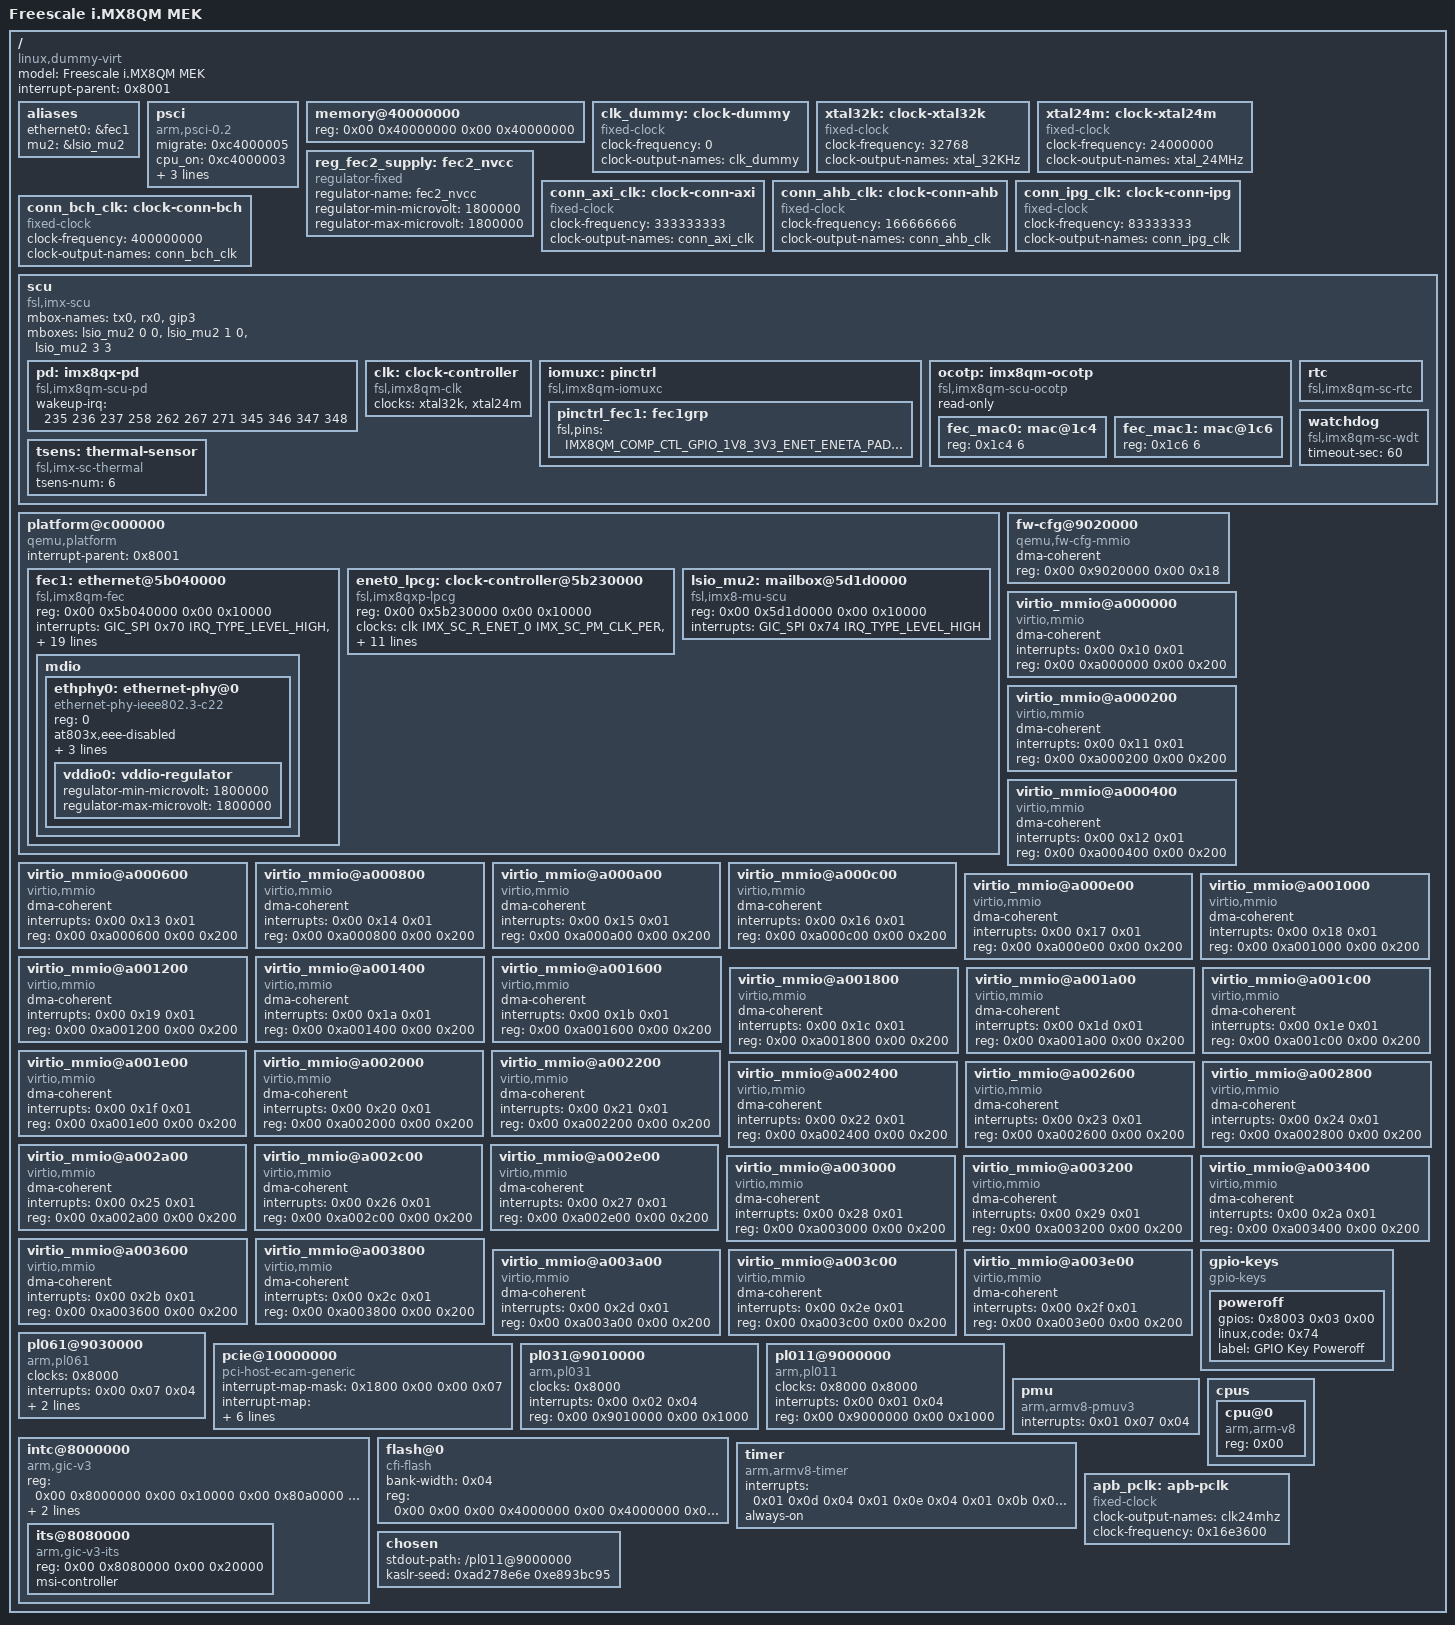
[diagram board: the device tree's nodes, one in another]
// SPDX-FileCopyrightText: 2022-2024 TII (SSRC) and the Ghaf contributors
//
// SPDX-License-Identifier: Apache-2.0

/dts-v1/;

#include <dt-bindings/clock/imx8-clock.h>
#include <dt-bindings/firmware/imx/rsrc.h>
#include <dt-bindings/gpio/gpio.h>
#include <dt-bindings/input/input.h>
#include <dt-bindings/usb/pd.h>
#include <dt-bindings/interrupt-controller/arm-gic.h>
#include <dt-bindings/pinctrl/pads-imx8qm.h>
#include <dt-bindings/soc/imx8_hsio.h>
#include <dt-bindings/thermal/thermal.h>

/ {
	model = "Freescale i.MX8QM MEK";
	interrupt-parent = <0x8001>;
	#size-cells = <0x02>;
	#address-cells = <0x02>;
	compatible = "linux,dummy-virt";

	aliases {
		ethernet0 = &fec1;
		mu2 = &lsio_mu2;
	};

	psci {
		migrate = <0xc4000005>;
		cpu_on = <0xc4000003>;
		cpu_off = <0x84000002>;
		cpu_suspend = <0xc4000001>;
		method = "hvc";
		compatible = "arm,psci-0.2\0arm,psci";
	};

	memory@40000000 {
		reg = <0x00 0x40000000 0x00 0x40000000>;
		device_type = "memory";
	};

	clk_dummy: clock-dummy {
		compatible = "fixed-clock";
		#clock-cells = <0>;
		clock-frequency = <0>;
		clock-output-names = "clk_dummy";
	};

	xtal32k: clock-xtal32k {
		compatible = "fixed-clock";
		#clock-cells = <0>;
		clock-frequency = <32768>;
		clock-output-names = "xtal_32KHz";
	};

	xtal24m: clock-xtal24m {
		compatible = "fixed-clock";
		#clock-cells = <0>;
		clock-frequency = <24000000>;
		clock-output-names = "xtal_24MHz";
	};

	reg_fec2_supply: fec2_nvcc {
		compatible = "regulator-fixed";
		regulator-name = "fec2_nvcc";
		regulator-min-microvolt = <1800000>;
		regulator-max-microvolt = <1800000>;
//		gpio = <&max7322 0 GPIO_ACTIVE_HIGH>;
		status = "okay";
	};

	conn_axi_clk: clock-conn-axi {
		compatible = "fixed-clock";
		#clock-cells = <0>;
		clock-frequency = <333333333>;
		clock-output-names = "conn_axi_clk";
	};

	conn_ahb_clk: clock-conn-ahb {
		compatible = "fixed-clock";
		#clock-cells = <0>;
		clock-frequency = <166666666>;
		clock-output-names = "conn_ahb_clk";
	};

	conn_ipg_clk: clock-conn-ipg {
		compatible = "fixed-clock";
		#clock-cells = <0>;
		clock-frequency = <83333333>;
		clock-output-names = "conn_ipg_clk";
	};

	conn_bch_clk: clock-conn-bch {
		compatible = "fixed-clock";
		#clock-cells = <0>;
		clock-frequency = <400000000>;
		clock-output-names = "conn_bch_clk";
	};

	scu {
		compatible = "fsl,imx-scu";
		mbox-names = "tx0", "rx0", "gip3";
		mboxes = <&lsio_mu2 0 0
			&lsio_mu2 1 0
			&lsio_mu2 3 3>;

		pd: imx8qx-pd {
			compatible = "fsl,imx8qm-scu-pd", "fsl,scu-pd";
			#power-domain-cells = <1>;
			status = "okay";
			wakeup-irq = <235 236 237 258 262 267 271
					345 346 347 348>;
		};

		clk: clock-controller {
			compatible = "fsl,imx8qm-clk", "fsl,scu-clk";
			#clock-cells = <2>;
			clocks = <&xtal32k &xtal24m>;
			clock-names = "xtal_32KHz", "xtal_24Mhz";
		};

		iomuxc: pinctrl {
			compatible = "fsl,imx8qm-iomuxc";
		};

		ocotp: imx8qm-ocotp {
			compatible = "fsl,imx8qm-scu-ocotp";
			#address-cells = <1>;
			#size-cells = <1>;
			read-only;

			fec_mac0: mac@1c4 {
				reg = <0x1c4 6>;
			};

			fec_mac1: mac@1c6 {
				reg = <0x1c6 6>;
			};
		};

		rtc: rtc {
			compatible = "fsl,imx8qm-sc-rtc";
		};

		watchdog {
			compatible = "fsl,imx8qm-sc-wdt", "fsl,imx-sc-wdt";
			timeout-sec = <60>;
		};

		tsens: thermal-sensor {
			compatible = "fsl,imx-sc-thermal";
			tsens-num = <6>;
			#thermal-sensor-cells = <1>;
		};
/*
		secvio: secvio {
			compatible = "fsl,imx-sc-secvio";
			nvmem = <&ocotp>;
		};
*/
	};

	platform@c000000 {
		compatible = "qemu,platform\0simple-bus";
		interrupt-parent = <0x8001>;
		#address-cells = <0x01>;
		#size-cells = <0x01>;

		// ranges = <0xc000000 0x00 0xc000000 0x2000000>;
		ranges = <0x00 0x5b230000 0x00 0xc000000 0x00 0x10000>,
				 <0x00 0x5b040000 0x00 0xc010000 0x00 0x10000>,
				 <0x00 0x5d1d0000 0x00 0xc020000 0x00 0x10000>;
				 

	fec1: ethernet@5b040000 {
		reg = <0x00 0x5b040000 0x00 0x10000>;

		interrupts = <GIC_SPI 258 IRQ_TYPE_LEVEL_HIGH>,
			     <GIC_SPI 256 IRQ_TYPE_LEVEL_HIGH>,
			     <GIC_SPI 257 IRQ_TYPE_LEVEL_HIGH>,
			     <GIC_SPI 259 IRQ_TYPE_LEVEL_HIGH>;

		clocks = <&enet0_lpcg 4>,
			 <&enet0_lpcg 2>,
			 <&enet0_lpcg 3>,
			 <&enet0_lpcg 0>,
			 <&enet0_lpcg 1>;
		clock-names = "ipg", "ahb", "enet_clk_ref", "ptp", "enet_2x_txclk";
		assigned-clocks = <&clk IMX_SC_R_ENET_0 IMX_SC_PM_CLK_PER>,
				  <&clk IMX_SC_R_ENET_0 IMX_SC_C_CLKDIV>;
		assigned-clock-rates = <250000000>, <125000000>;
		fsl,num-tx-queues=<1>;
		fsl,num-rx-queues=<1>;
		power-domains = <&pd IMX_SC_R_ENET_0>;
		status = "disabled";
	};

	enet0_lpcg: clock-controller@5b230000 {
		compatible = "fsl,imx8qxp-lpcg";
		reg = <0x00 0x5b230000 0x00 0x10000>;
		#clock-cells = <1>;
		clocks = <&clk IMX_SC_R_ENET_0 IMX_SC_PM_CLK_PER>,
			 <&clk IMX_SC_R_ENET_0 IMX_SC_PM_CLK_PER>,
			 <&conn_axi_clk>,
			 <&clk IMX_SC_R_ENET_0 IMX_SC_C_TXCLK>,
			 <&conn_ipg_clk>,
			 <&conn_ipg_clk>;
		bit-offset = <0 4 8 12 16 20>;
		clock-output-names = "enet0_lpcg_timer_clk",
					"enet0_lpcg_txc_sampling_clk",
					"enet0_lpcg_ahb_clk",
					"enet0_lpcg_rgmii_txc_clk",
					"enet0_lpcg_ipg_clk",
					"enet0_lpcg_ipg_s_clk";
		power-domains = <&pd IMX_SC_R_ENET_0>;
		status = "disabled";
	};

		lsio_mu2: mailbox@5d1d0000 {
			compatible = "fsl,imx8-mu-scu", "fsl,imx8qm-mu", "fsl,imx6sx-mu";
			reg = <0x00 0x5d1d0000 0x00 0x10000>;
			interrupts = <GIC_SPI 178 IRQ_TYPE_LEVEL_HIGH>;
			#mbox-cells = <0x02>;
			status = "disabled";
		};
	};

	fw-cfg@9020000 {
		dma-coherent;
		reg = <0x00 0x9020000 0x00 0x18>;
		compatible = "qemu,fw-cfg-mmio";
	};

	virtio_mmio@a000000 {
		dma-coherent;
		interrupts = <0x00 0x10 0x01>;
		reg = <0x00 0xa000000 0x00 0x200>;
		compatible = "virtio,mmio";
	};

	virtio_mmio@a000200 {
		dma-coherent;
		interrupts = <0x00 0x11 0x01>;
		reg = <0x00 0xa000200 0x00 0x200>;
		compatible = "virtio,mmio";
	};

	virtio_mmio@a000400 {
		dma-coherent;
		interrupts = <0x00 0x12 0x01>;
		reg = <0x00 0xa000400 0x00 0x200>;
		compatible = "virtio,mmio";
	};

	virtio_mmio@a000600 {
		dma-coherent;
		interrupts = <0x00 0x13 0x01>;
		reg = <0x00 0xa000600 0x00 0x200>;
		compatible = "virtio,mmio";
	};

	virtio_mmio@a000800 {
		dma-coherent;
		interrupts = <0x00 0x14 0x01>;
		reg = <0x00 0xa000800 0x00 0x200>;
		compatible = "virtio,mmio";
	};

	virtio_mmio@a000a00 {
		dma-coherent;
		interrupts = <0x00 0x15 0x01>;
		reg = <0x00 0xa000a00 0x00 0x200>;
		compatible = "virtio,mmio";
	};

	virtio_mmio@a000c00 {
		dma-coherent;
		interrupts = <0x00 0x16 0x01>;
		reg = <0x00 0xa000c00 0x00 0x200>;
		compatible = "virtio,mmio";
	};

	virtio_mmio@a000e00 {
		dma-coherent;
		interrupts = <0x00 0x17 0x01>;
		reg = <0x00 0xa000e00 0x00 0x200>;
		compatible = "virtio,mmio";
	};

	virtio_mmio@a001000 {
		dma-coherent;
		interrupts = <0x00 0x18 0x01>;
		reg = <0x00 0xa001000 0x00 0x200>;
		compatible = "virtio,mmio";
	};

	virtio_mmio@a001200 {
		dma-coherent;
		interrupts = <0x00 0x19 0x01>;
		reg = <0x00 0xa001200 0x00 0x200>;
		compatible = "virtio,mmio";
	};

	virtio_mmio@a001400 {
		dma-coherent;
		interrupts = <0x00 0x1a 0x01>;
		reg = <0x00 0xa001400 0x00 0x200>;
		compatible = "virtio,mmio";
	};

	virtio_mmio@a001600 {
		dma-coherent;
		interrupts = <0x00 0x1b 0x01>;
		reg = <0x00 0xa001600 0x00 0x200>;
		compatible = "virtio,mmio";
	};

	virtio_mmio@a001800 {
		dma-coherent;
		interrupts = <0x00 0x1c 0x01>;
		reg = <0x00 0xa001800 0x00 0x200>;
		compatible = "virtio,mmio";
	};

	virtio_mmio@a001a00 {
		dma-coherent;
		interrupts = <0x00 0x1d 0x01>;
		reg = <0x00 0xa001a00 0x00 0x200>;
		compatible = "virtio,mmio";
	};

	virtio_mmio@a001c00 {
		dma-coherent;
		interrupts = <0x00 0x1e 0x01>;
		reg = <0x00 0xa001c00 0x00 0x200>;
		compatible = "virtio,mmio";
	};

	virtio_mmio@a001e00 {
		dma-coherent;
		interrupts = <0x00 0x1f 0x01>;
		reg = <0x00 0xa001e00 0x00 0x200>;
		compatible = "virtio,mmio";
	};

	virtio_mmio@a002000 {
		dma-coherent;
		interrupts = <0x00 0x20 0x01>;
		reg = <0x00 0xa002000 0x00 0x200>;
		compatible = "virtio,mmio";
	};

	virtio_mmio@a002200 {
		dma-coherent;
		interrupts = <0x00 0x21 0x01>;
		reg = <0x00 0xa002200 0x00 0x200>;
		compatible = "virtio,mmio";
	};

	virtio_mmio@a002400 {
		dma-coherent;
		interrupts = <0x00 0x22 0x01>;
		reg = <0x00 0xa002400 0x00 0x200>;
		compatible = "virtio,mmio";
	};

	virtio_mmio@a002600 {
		dma-coherent;
		interrupts = <0x00 0x23 0x01>;
		reg = <0x00 0xa002600 0x00 0x200>;
		compatible = "virtio,mmio";
	};

	virtio_mmio@a002800 {
		dma-coherent;
		interrupts = <0x00 0x24 0x01>;
		reg = <0x00 0xa002800 0x00 0x200>;
		compatible = "virtio,mmio";
	};

	virtio_mmio@a002a00 {
		dma-coherent;
		interrupts = <0x00 0x25 0x01>;
		reg = <0x00 0xa002a00 0x00 0x200>;
		compatible = "virtio,mmio";
	};

	virtio_mmio@a002c00 {
		dma-coherent;
		interrupts = <0x00 0x26 0x01>;
		reg = <0x00 0xa002c00 0x00 0x200>;
		compatible = "virtio,mmio";
	};

	virtio_mmio@a002e00 {
		dma-coherent;
		interrupts = <0x00 0x27 0x01>;
		reg = <0x00 0xa002e00 0x00 0x200>;
		compatible = "virtio,mmio";
	};

	virtio_mmio@a003000 {
		dma-coherent;
		interrupts = <0x00 0x28 0x01>;
		reg = <0x00 0xa003000 0x00 0x200>;
		compatible = "virtio,mmio";
	};

	virtio_mmio@a003200 {
		dma-coherent;
		interrupts = <0x00 0x29 0x01>;
		reg = <0x00 0xa003200 0x00 0x200>;
		compatible = "virtio,mmio";
	};

	virtio_mmio@a003400 {
		dma-coherent;
		interrupts = <0x00 0x2a 0x01>;
		reg = <0x00 0xa003400 0x00 0x200>;
		compatible = "virtio,mmio";
	};

	virtio_mmio@a003600 {
		dma-coherent;
		interrupts = <0x00 0x2b 0x01>;
		reg = <0x00 0xa003600 0x00 0x200>;
		compatible = "virtio,mmio";
	};

	virtio_mmio@a003800 {
		dma-coherent;
		interrupts = <0x00 0x2c 0x01>;
		reg = <0x00 0xa003800 0x00 0x200>;
		compatible = "virtio,mmio";
	};

	virtio_mmio@a003a00 {
		dma-coherent;
		interrupts = <0x00 0x2d 0x01>;
		reg = <0x00 0xa003a00 0x00 0x200>;
		compatible = "virtio,mmio";
	};

	virtio_mmio@a003c00 {
		dma-coherent;
		interrupts = <0x00 0x2e 0x01>;
		reg = <0x00 0xa003c00 0x00 0x200>;
		compatible = "virtio,mmio";
	};

	virtio_mmio@a003e00 {
		dma-coherent;
		interrupts = <0x00 0x2f 0x01>;
		reg = <0x00 0xa003e00 0x00 0x200>;
		compatible = "virtio,mmio";
	};

	gpio-keys {
		#address-cells = <0x01>;
		#size-cells = <0x00>;
		compatible = "gpio-keys";

		poweroff {
			gpios = <0x8003 0x03 0x00>;
			linux,code = <0x74>;
			label = "GPIO Key Poweroff";
		};
	};

	pl061@9030000 {
		phandle = <0x8003>;
		clock-names = "apb_pclk";
		clocks = <0x8000>;
		interrupts = <0x00 0x07 0x04>;
		gpio-controller;
		#gpio-cells = <0x02>;
		compatible = "arm,pl061\0arm,primecell";
		reg = <0x00 0x9030000 0x00 0x1000>;
	};

	pcie@10000000 {
		interrupt-map-mask = <0x1800 0x00 0x00 0x07>;
		interrupt-map = <0x00 0x00 0x00 0x01 0x8001 0x00 0x00 0x00 0x03 0x04 0x00 0x00 0x00 0x02 0x8001 0x00 0x00 0x00 0x04 0x04 0x00 0x00 0x00 0x03 0x8001 0x00 0x00 0x00 0x05 0x04 0x00 0x00 0x00 0x04 0x8001 0x00 0x00 0x00 0x06 0x04 0x800 0x00 0x00 0x01 0x8001 0x00 0x00 0x00 0x04 0x04 0x800 0x00 0x00 0x02 0x8001 0x00 0x00 0x00 0x05 0x04 0x800 0x00 0x00 0x03 0x8001 0x00 0x00 0x00 0x06 0x04 0x800 0x00 0x00 0x04 0x8001 0x00 0x00 0x00 0x03 0x04 0x1000 0x00 0x00 0x01 0x8001 0x00 0x00 0x00 0x05 0x04 0x1000 0x00 0x00 0x02 0x8001 0x00 0x00 0x00 0x06 0x04 0x1000 0x00 0x00 0x03 0x8001 0x00 0x00 0x00 0x03 0x04 0x1000 0x00 0x00 0x04 0x8001 0x00 0x00 0x00 0x04 0x04 0x1800 0x00 0x00 0x01 0x8001 0x00 0x00 0x00 0x06 0x04 0x1800 0x00 0x00 0x02 0x8001 0x00 0x00 0x00 0x03 0x04 0x1800 0x00 0x00 0x03 0x8001 0x00 0x00 0x00 0x04 0x04 0x1800 0x00 0x00 0x04 0x8001 0x00 0x00 0x00 0x05 0x04>;
		#interrupt-cells = <0x01>;
		ranges = <0x1000000 0x00 0x00 0x00 0x3eff0000 0x00 0x10000 0x2000000 0x00 0x10000000 0x00 0x10000000 0x00 0x2eff0000 0x3000000 0x80 0x00 0x80 0x00 0x80 0x00>;
		reg = <0x40 0x10000000 0x00 0x10000000>;
		msi-parent = <0x8002>;
		dma-coherent;
		bus-range = <0x00 0xff>;
		linux,pci-domain = <0x00>;
		#size-cells = <0x02>;
		#address-cells = <0x03>;
		device_type = "pci";
		compatible = "pci-host-ecam-generic";
	};

	pl031@9010000 {
		clock-names = "apb_pclk";
		clocks = <0x8000>;
		interrupts = <0x00 0x02 0x04>;
		reg = <0x00 0x9010000 0x00 0x1000>;
		compatible = "arm,pl031\0arm,primecell";
	};

	pl011@9000000 {
		clock-names = "uartclk\0apb_pclk";
		clocks = <0x8000 0x8000>;
		interrupts = <0x00 0x01 0x04>;
		reg = <0x00 0x9000000 0x00 0x1000>;
		compatible = "arm,pl011\0arm,primecell";
	};

	pmu {
		interrupts = <0x01 0x07 0x04>;
		compatible = "arm,armv8-pmuv3";
	};

	intc@8000000 {
		phandle = <0x8001>;
		reg = <0x00 0x8000000 0x00 0x10000 0x00 0x80a0000 0x00 0xf60000>;
		#redistributor-regions = <0x01>;
		compatible = "arm,gic-v3";
		ranges;
		#size-cells = <0x02>;
		#address-cells = <0x02>;
		interrupt-controller;
		#interrupt-cells = <0x03>;

		its@8080000 {
			phandle = <0x8002>;
			reg = <0x00 0x8080000 0x00 0x20000>;
			msi-controller;
			compatible = "arm,gic-v3-its";
		};
	};

	flash@0 {
		bank-width = <0x04>;
		reg = <0x00 0x00 0x00 0x4000000 0x00 0x4000000 0x00 0x4000000>;
		compatible = "cfi-flash";
	};

	cpus {
		#size-cells = <0x00>;
		#address-cells = <0x01>;

		cpu@0 {
			reg = <0x00>;
			compatible = "arm,arm-v8";
			device_type = "cpu";
		};
	};

	timer {
		interrupts = <0x01 0x0d 0x04 0x01 0x0e 0x04 0x01 0x0b 0x04 0x01 0x0a 0x04>;
		always-on;
		compatible = "arm,armv8-timer\0arm,armv7-timer";
	};

	apb_pclk: apb-pclk {
		phandle = <0x8000>;
		clock-output-names = "clk24mhz";
		clock-frequency = <0x16e3600>;
		#clock-cells = <0x00>;
		compatible = "fixed-clock";
	};

	chosen {
		stdout-path = "/pl011@9000000";
		kaslr-seed = <0xad278e6e 0xe893bc95>;
	};

};

&fec1 {
	compatible = "fsl,imx8qm-fec", "fsl,imx6sx-fec";
	interrupts = <GIC_SPI 0x70 IRQ_TYPE_LEVEL_HIGH>,
			<GIC_SPI 0x71 IRQ_TYPE_LEVEL_HIGH>,
			<GIC_SPI 0x72 IRQ_TYPE_LEVEL_HIGH>,
			<GIC_SPI 0x73 IRQ_TYPE_LEVEL_HIGH>;

	/delete-property/ iommus;

	pinctrl-names = "default";
	pinctrl-0 = <&pinctrl_fec1>;
	phy-mode = "rgmii-txid";
	phy-handle = <&ethphy0>;
	fsl,magic-packet;
	nvmem-cells = <&fec_mac0>;
	nvmem-cell-names = "mac-address";
	fsl,wakeup_irq = <0>;

	status = "okay";

	mdio {
		#address-cells = <1>;
		#size-cells = <0>;

		ethphy0: ethernet-phy@0 {
			compatible = "ethernet-phy-ieee802.3-c22";
			reg = <0>;
			at803x,eee-disabled;
			at803x,vddio-1p8v;
			qca,disable-smarteee;
			vddio-supply = <&vddio0>;

			vddio0: vddio-regulator {
				regulator-min-microvolt = <1800000>;
				regulator-max-microvolt = <1800000>;
			};
		};
	};
};

&enet0_lpcg {
	status = "okay";
	/delete-property/ iommus;
};

&lsio_mu2 {
	compatible = "fsl,imx8-mu-scu", "fsl,imx8qm-mu", "fsl,imx6sx-mu";
	interrupts = <GIC_SPI 0x74 IRQ_TYPE_LEVEL_HIGH>;
	/delete-property/ iommus;
	status = "okay";
};

&iomuxc {
	pinctrl-names = "default";
	status = "okay";

	pinctrl_fec1: fec1grp {
		fsl,pins = <
			IMX8QM_COMP_CTL_GPIO_1V8_3V3_ENET_ENETA_PAD		0x000014a0
			IMX8QM_ENET0_MDC_CONN_ENET0_MDC				0x06000020
			IMX8QM_ENET0_MDIO_CONN_ENET0_MDIO			0x06000020
			IMX8QM_ENET0_RGMII_TX_CTL_CONN_ENET0_RGMII_TX_CTL	0x06000020
			IMX8QM_ENET0_RGMII_TXC_CONN_ENET0_RGMII_TXC		0x06000020
			IMX8QM_ENET0_RGMII_TXD0_CONN_ENET0_RGMII_TXD0		0x06000020
			IMX8QM_ENET0_RGMII_TXD1_CONN_ENET0_RGMII_TXD1		0x06000020
			IMX8QM_ENET0_RGMII_TXD2_CONN_ENET0_RGMII_TXD2		0x06000020
			IMX8QM_ENET0_RGMII_TXD3_CONN_ENET0_RGMII_TXD3		0x06000020
			IMX8QM_ENET0_RGMII_RXC_CONN_ENET0_RGMII_RXC		0x06000020
			IMX8QM_ENET0_RGMII_RX_CTL_CONN_ENET0_RGMII_RX_CTL	0x06000020
			IMX8QM_ENET0_RGMII_RXD0_CONN_ENET0_RGMII_RXD0		0x06000020
			IMX8QM_ENET0_RGMII_RXD1_CONN_ENET0_RGMII_RXD1		0x06000020
			IMX8QM_ENET0_RGMII_RXD2_CONN_ENET0_RGMII_RXD2		0x06000020
			IMX8QM_ENET0_RGMII_RXD3_CONN_ENET0_RGMII_RXD3		0x06000020
		>;
	};
};
